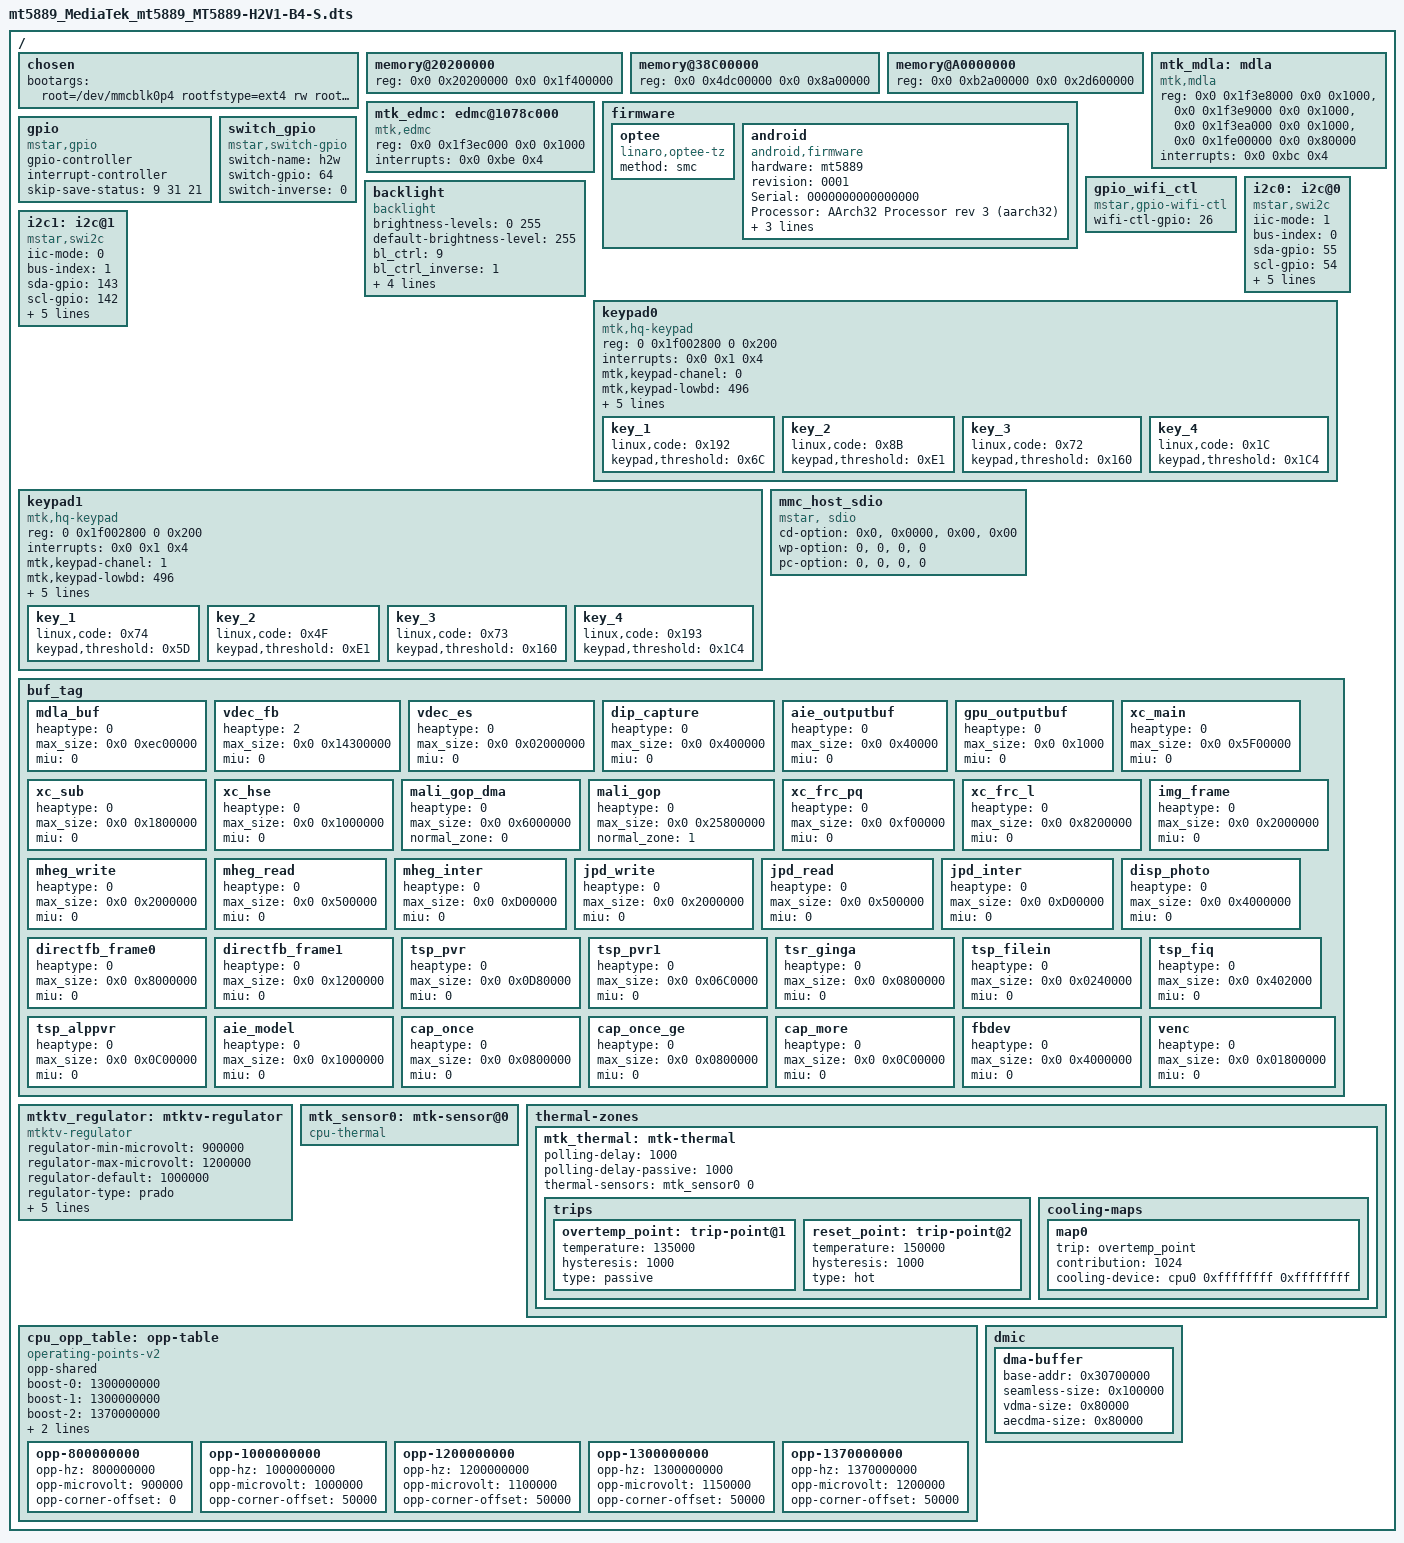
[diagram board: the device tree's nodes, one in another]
/*
 * ARM Ltd.
 *
 * ARMv8 Foundation model DTS
 */

/dts-v1/;
#include "mt5889.dtsi"
#include "cpuqos_v1.dtsi"

/ {
	chosen {
		bootargs = "root=/dev/mmcblk0p4 rootfstype=ext4 rw rootwait init=/sbin/init ip=dhcp console=ttyS0,115200,LX_MEM=0x02000000";
	};

	memory@20200000 {
		device_type = "memory";
		reg = <0x0 0x20200000 0x0 0x1f400000>;
	};

	memory@38C00000 {
		device_type = "memory";
		reg = <0x0 0x4dc00000 0x0 0x8a00000>;
	};

	memory@A0000000 {
		device_type = "memory";
		reg = <0x0 0xb2a00000 0x0 0x2d600000>;
	};

	mtk_mdla: mdla {
		  compatible = "mtk,mdla";
		  reg =   <0x0 0x1f3e8000 0x0 0x1000>,
		      <0x0 0x1f3e9000 0x0 0x1000>,
		      <0x0 0x1f3ea000 0x0 0x1000>,
		      <0x0 0x1fe00000 0x0 0x80000>;
		  interrupts = <0x0 0xbc 0x4>;
	};

	mtk_edmc: edmc@1078c000 {
		  compatible = "mtk,edmc";
		  reg = <0x0 0x1f3ec000 0x0 0x1000>;
		  interrupts = <0x0 0xbe 0x4>;
	};

	firmware {
                optee {
                        compatible = "linaro,optee-tz";
                        method = "smc";
                };
		android {
			compatible = "android,firmware";
			hardware ="mt5889";
			revision ="0001";
			Serial   ="0000000000000000";
			Processor ="AArch32 Processor rev 3 (aarch32)";
			mode ="20170621";
			baseband ="20170621";
			bootloader ="20170621";
		};
	};

	/* example of consume a gpio pin with mapped irq
	foo{
		interrupt-parent = <&gpio>;
		interrupts = <0 LEVEL_HIGH>;
	}
	*/

	gpio: gpio {
		compatible = "mstar,gpio";
		gpio-controller;
		#gpio-cells = <1>;
		interrupt-controller;
		skip-save-status = <9 31 21>;
		#interrupt-cells = <2>; /* cell name GPIO_PAD, trigger-type*/
	};

	switch_gpio {
		compatible = "mstar,switch-gpio";
		switch-name = "h2w";
		switch-gpio = <64>;
		switch-inverse = <0>;
	};

	gpio_wifi_ctl {
		compatible = "mstar,gpio-wifi-ctl";
		wifi-ctl-gpio = <26>;
	};

	backlight {
		compatible = "backlight";
		brightness-levels = <0 255>;
		default-brightness-level = <255>;
		bl_ctrl = <9>;
		bl_ctrl_inverse = <1>;
		vcc_gpio = <31>;
		vcc_gpio_invert = <1>;
		led_gpio = <21>;
		led_gpio_invert = <0>;
		/* led-pwm-control-support; */
		/* led-pwm-control-channel = <0>; */
		/* led-pwm-control-resume-period = <0xb71a>; */
		/* led-pwm-control-resume-duty = <0xb71a>; */
		/* led-pwm-control-resume-div = <0xff>; */
		/* led-pwm-control-resume-polarity = <0>; */
		/* led-pwm-control-suspend-period = <0xb71a>; */
		/* led-pwm-control-suspend-duty = <0xb71a>; */
		/* led-pwm-control-suspend-div = <0xff>; */
		/* led-pwm-control-suspend-polarity = <0>; */
	};

	i2c0: i2c@0 {
		compatible = "mstar,swi2c";
		iic-mode = <1>;	 /* i2c-mode: 0:swi2c; 1:hwi2c */
		bus-index = <0>;	/* swi2c setting: bus index */
		sda-gpio = <55>;	/* swi2c setting: sda pad */
		scl-gpio = <54>;	/* swi2c setting: scl pad */
		def-delay = <100>;  /* swi2c setting: clk */
		hw-port = <3>;	  /* hwi2c setting: port */
		pad-mux = <25>;	 /* hwi2c setting: pad mux */
		speed-khz = <100>;  /* hwi2c setting: clk */
		retries = <5>;	  /* Unused */
		status = "okay";	/* Unused */
	};

	i2c1: i2c@1 {
		compatible = "mstar,swi2c";
		iic-mode = <0>;	 /* i2c-mode: 0:swi2c; 1:hwi2c */
		bus-index = <1>;	/* swi2c setting: bus index */
		sda-gpio = <143>;   /* swi2c setting: sda pad */
		scl-gpio = <142>;   /* swi2c setting: scl pad */
		def-delay = <100>;  /* swi2c setting: clk */
		hw-port = <0>;	  /* hwi2c setting: port */
		pad-mux = <0>;	  /* hwi2c setting: pad mux */
		speed-khz = <100>;  /* hwi2c setting: clk */
		retries = <5>;	  /* Unused */
		status = "okay";	/* Unused */
	};

    keypad0{
		compatible = "mtk,hq-keypad";
		reg = <0 0x1f002800 0 0x200>;
		interrupts = <0x0 0x1 0x4>;
		mtk,keypad-chanel = <0>;
		mtk,keypad-lowbd = <496>;
		mtk,keypad-upwbd = <1023>;
		mtk,keypad-num = <4>;
		linux,input-no-autorepeat;
		mtk,keypad-releaseadc = <0x220>;
		wakeup-source;

		key_1 {
			linux,code = <0x192>;
			keypad,threshold = <0x6C>;
		};

		key_2 {
			linux,code = <0x8B>;
			keypad,threshold = <0xE1>;
		};

		key_3 {
			linux,code = <0x72>;
			keypad,threshold = <0x160>;
		};

		key_4 {
			linux,code = <0x1C>;
			keypad,threshold = <0x1C4>;
		};
	};

    keypad1{
		compatible = "mtk,hq-keypad";
		reg = <0 0x1f002800 0 0x200>;
		interrupts = <0x0 0x1 0x4>;
		mtk,keypad-chanel = <1>;
		mtk,keypad-lowbd = <496>;
		mtk,keypad-upwbd = <1023>;
		mtk,keypad-num = <4>;
		linux,input-no-autorepeat;
		mtk,keypad-releaseadc = <0x220>;
		wakeup-source;

		key_1 {
			linux,code = <0x74>;
			keypad,threshold = <0x5D>;
		};

		key_2 {
			linux,code = <0x4F>;
			keypad,threshold = <0xE1>;
		};

		key_3 {
			linux,code = <0x73>;
			keypad,threshold = <0x160>;
		};

		key_4 {
			linux,code = <0x193>;
			keypad,threshold = <0x1C4>;
		};
	};

	mmc_host_sdio {
		compatible = "mstar, sdio";
		cd-option = <0x0>,<0x0000>,<0x00>,<0x00>;
		wp-option = <0>,<0>,<0>,<0>;
		pc-option =  <0>,<0>,<0>,<0>;
	};

	buf_tag {
	/* heaptype: HEAP_TYPE_IOMMU = 0, HEAP_TYPE_CMA= 1,  HEAP_TYPE_NON_MMA = 2*/
	/* miutype:  UMA_OR_MIU0 = 0, MIU_1 = 1 */
		mdla_buf {
			heaptype = <0>;
			max_size = <0x0 0xec00000>;
			miu = <0>;
		};
		vdec_fb {
			heaptype = <2>;
			max_size = <0x0 0x14300000>;
			miu = <0>;
		};
		vdec_es {
			heaptype = <0>;
			max_size = <0x0 0x02000000>;
			miu = <0>;
		};
		dip_capture {
			heaptype = <0>;
			max_size = <0x0 0x400000>;
			miu = <0>;
		};
		aie_outputbuf {
			heaptype = <0>;
			max_size = <0x0 0x40000>;
			miu = <0>;
		};
                gpu_outputbuf {
			heaptype = <0>;
			max_size = <0x0 0x1000>;
			miu = <0>;
		};
		xc_main {
			heaptype = <0>;
			max_size = <0x0 0x5F00000>;
			miu = <0>;
		};
		xc_sub {
			heaptype = <0>;
			max_size = <0x0 0x1800000>;
			miu = <0>;
		};
		xc_hse {
			heaptype = <0>;
			max_size = <0x0 0x1000000>;
			miu = <0>;
		};
		mali_gop_dma {
			heaptype = <0>;
			max_size = <0x0 0x6000000>;
			normal_zone = <0>;
		};
		mali_gop {
			heaptype = <0>;
			max_size = <0x0 0x25800000>;
			normal_zone = <1>;
		};
		xc_frc_pq {
			heaptype = <0>;
			max_size = <0x0 0xf00000>;
			miu = <0>;
		};
		xc_frc_l {
			heaptype = <0>;
			max_size = <0x0 0x8200000>;
			miu = <0>;
		};
		img_frame {
			heaptype = <0>;
			max_size = <0x0 0x2000000>;
			miu = <0>;
		};
		mheg_write {
			heaptype = <0>;
			max_size = <0x0 0x2000000>;
			miu = <0>;
		};
		mheg_read {
			heaptype = <0>;
			max_size = <0x0 0x500000>;
			miu = <0>;
		};
		mheg_inter {
			heaptype = <0>;
			max_size = <0x0 0xD00000>;
			miu = <0>;
		};
		jpd_write {
			heaptype = <0>;
			max_size = <0x0 0x2000000>;
			miu = <0>;
		};
		jpd_read {
			heaptype = <0>;
			max_size = <0x0 0x500000>;
			miu = <0>;
		};
		jpd_inter {
			heaptype = <0>;
			max_size = <0x0 0xD00000>;
			miu = <0>;
		};
		disp_photo {
			heaptype = <0>;
			max_size = <0x0 0x4000000>;
			miu = <0>;
		};
		directfb_frame0 {
			heaptype = <0>;
			max_size = <0x0 0x8000000>;
			miu = <0>;
		};
		directfb_frame1 {
			heaptype = <0>;
			max_size = <0x0 0x1200000>;
			miu = <0>;
		};
		tsp_pvr {
			heaptype = <0>;
			max_size = <0x0 0x0D80000>;
			miu = <0>;
		};
		tsp_pvr1 {
			heaptype = <0>;
			max_size = <0x0 0x06C0000>;
			miu = <0>;
		};
        tsr_ginga {
             heaptype = <0>;
             max_size = <0x0 0x0800000>;
             miu = <0>;
         };
		tsp_filein {
			heaptype = <0>;
			max_size = <0x0 0x0240000>;
			miu = <0>;
		};
		tsp_fiq {
			heaptype = <0>;
			max_size = <0x0 0x402000>;
			miu = <0>;
		};
		tsp_alppvr {
			heaptype = <0>;
			max_size = <0x0 0x0C00000>;
			miu = <0>;
		};
		aie_model {
			heaptype = <0>;
			max_size = <0x0 0x1000000>;
			miu = <0>;
		};
		cap_once {
			heaptype = <0>;
			max_size = <0x0 0x0800000>;
			miu = <0>;
		};
		cap_once_ge {
			heaptype = <0>;
			max_size = <0x0 0x0800000>;
			miu = <0>;
		};
		cap_more {
			heaptype = <0>;
			max_size = <0x0 0x0C00000>;
			miu = <0>;
		};
		fbdev {
			heaptype = <0>;
			max_size = <0x0 0x4000000>;
			miu = <0>;
		};
		venc {
			heaptype = <0>;
			max_size = <0x0 0x01800000>;
			miu = <0>;
		};
	};

	mtktv_regulator: mtktv-regulator {
		compatible = "mtktv-regulator";
		regulator-min-microvolt = <900000>;
		regulator-max-microvolt = <1200000>;
		regulator-default = <1000000>;

		/* prado regulator */
		regulator-type = "prado";
		regulator-id = <0x9A>;
		regulator-step = <3>;
		regulator-shift = <68>;
		regulator-port = <3>;
		regulator-addr = <0x80>;
		/* pwm regulator */
		/*
		regulator-type = "pwm";
		regulator-channel = <0>;
		regulator-scale = <1950>;
		regulator-offset = <0>;
		regulator-auto = <1>;
		*/
		/* gpio regulator */
		/*
		regulator-type = "gpio";
		regulator-level = <2>;
		regulator-parm {
			control_0 {
				power = <95>;
				pins = <2>;
				gpio_num = <51 52>;
				gpio_mode = <0 1>;
			};
			control_1 {
				power = <100>;
				pins = <2>;
				gpio_num = <51 52>;
				gpio_mode = <1 1>;
			};
		};
		*/
	};

	mtk_sensor0: mtk-sensor@0 {
		compatible = "cpu-thermal";
		#thermal-sensor-cells = <1>;
	};

	thermal-zones {
		mtk_thermal: mtk-thermal {
			polling-delay = <1000>;
			polling-delay-passive = <1000>;

			thermal-sensors = <&mtk_sensor0 0>;
			trips {
				overtemp_point: trip-point@1 {
					temperature = <135000>; /* millicelsius */
					hysteresis = <1000>; /* millicelsius */
					type = "passive";
				};
				reset_point: trip-point@2 {
					temperature = <150000>; /* millicelsius */
					hysteresis = <1000>; /* millicelsius */
					type = "hot";
				};
			};
			cooling-maps {
				map0 {
					trip = <&overtemp_point>;
					contribution = <1024>;
					cooling-device = <&cpu0 0xffffffff 0xffffffff>;
				};
			};
		};
	};

	cpu_opp_table: opp-table {
		compatible = "operating-points-v2";
		opp-shared;

		boost-0 = <1300000000>;
		boost-1 = <1300000000>;
		boost-2 = <1370000000>;
		boost-3 = <1300000000>;
		boost-4 = <1300000000>;

		opp-800000000 {
			opp-hz = /bits/ 64 <800000000>;
			opp-microvolt = <900000>;
			opp-corner-offset = <0>;
		};

		opp-1000000000 {
			opp-hz = /bits/ 64 <1000000000>;
			opp-microvolt = <1000000>;
			opp-corner-offset = <50000>;
		};

		opp-1200000000 {
			opp-hz = /bits/ 64 <1200000000>;
			opp-microvolt = <1100000>;
			opp-corner-offset = <50000>;
		};

		opp-1300000000 {
			opp-hz = /bits/ 64 <1300000000>;
			opp-microvolt = <1150000>;
			opp-corner-offset = <50000>;
			};

		opp-1370000000 {
			opp-hz = /bits/ 64 <1370000000>;
			opp-microvolt = <1200000>;
			opp-corner-offset = <50000>;
		};

	};
	dmic {
		dma-buffer {
			base-addr = <0x30700000>;
			seamless-size = <0x100000>;
			vdma-size = <0x80000>;
			aecdma-size = <0x80000>;
		};
	};
};
